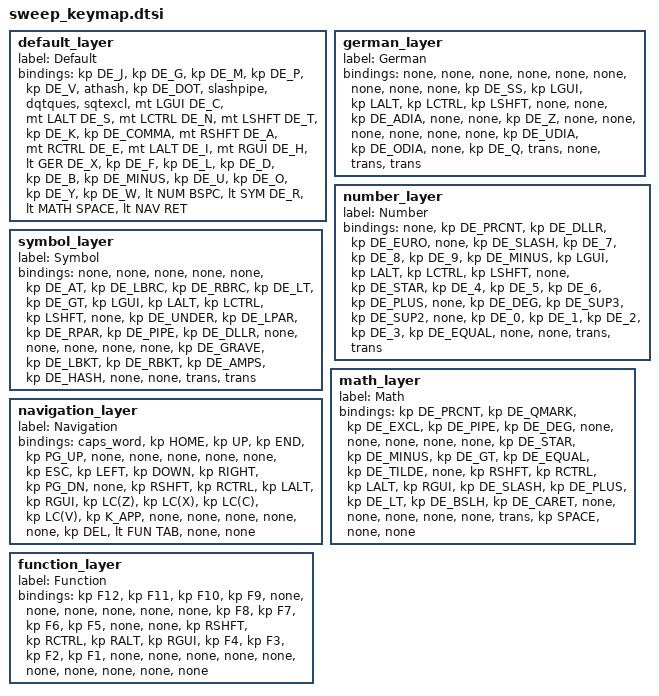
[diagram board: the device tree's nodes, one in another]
default_layer {
	label = "Default";
	bindings = <
	// --------------+---------------+---------------+---------------+--------------||---------------+---------------+---------------+---------------+---------------|
		&kp DE_J		&kp DE_G		&kp DE_M		&kp DE_P		&kp DE_V		&athash			&kp DE_DOT		&slashpipe		&dqtques		&sqtexcl 
	// --------------+---------------+---------------+---------------+--------------||---------------+---------------+---------------+---------------+---------------|
		&mt LGUI DE_C	&mt LALT DE_S	&mt LCTRL DE_N	&mt LSHFT DE_T	&kp DE_K		&kp DE_COMMA	&mt RSHFT DE_A	&mt RCTRL DE_E 	&mt LALT DE_I	&mt RGUI DE_H
	// --------------+---------------+---------------+---------------+--------------||---------------+---------------+---------------+---------------+---------------|
		&lt GER DE_X	&kp DE_F		&kp DE_L		&kp DE_D		&kp DE_B		&kp DE_MINUS   	&kp DE_U		&kp DE_O		&kp DE_Y		&kp DE_W	
	// --------------+---------------+---------------+---------------+--------------||---------------+---------------+---------------+---------------+---------------|
														&lt NUM BSPC	&lt SYM DE_R	&lt MATH SPACE	&lt NAV RET
							        				//---------------+--------------||---------------+---------------|
	>;
};

german_layer {
	label = "German";
	bindings = <
	// --------------+---------------+---------------+---------------+--------------||---------------+---------------+---------------+---------------+---------------|
		&none			&none			&none			&none			&none			&none			&none			&none			&none			&kp DE_SS 
	// --------------+---------------+---------------+---------------+--------------||---------------+---------------+---------------+---------------+---------------|
		&kp LGUI		&kp LALT		&kp LCTRL		&kp LSHFT		&none			&none			&kp DE_ADIA		&none			&none			&kp DE_Z
	// --------------+---------------+---------------+---------------+--------------||---------------+---------------+---------------+---------------+---------------|
		&none			&none			&none			&none			&none			&none	   		&kp DE_UDIA		&kp DE_ODIA		&none			&kp DE_Q	
	// --------------+---------------+---------------+---------------+--------------||---------------+---------------+---------------+---------------+---------------|
														&trans			&none			&trans			&trans
							            			//---------------+--------------||---------------+---------------|
	>;
};

number_layer {
	label = "Number";
	bindings = <
	// --------------+---------------+---------------+---------------+--------------||---------------+---------------+---------------+---------------+---------------|
		&none			&kp DE_PRCNT	&kp DE_DLLR		&kp DE_EURO		&none			&kp DE_SLASH	&kp DE_7		&kp DE_8		&kp DE_9		&kp DE_MINUS 
	// --------------+---------------+---------------+---------------+--------------||---------------+---------------+---------------+---------------+---------------|
		&kp LGUI		&kp LALT		&kp LCTRL		&kp LSHFT		&none			&kp DE_STAR		&kp DE_4		&kp DE_5		&kp DE_6		&kp DE_PLUS
	// --------------+---------------+---------------+---------------+--------------||---------------+---------------+---------------+---------------+---------------|
		&none			&kp DE_DEG		&kp DE_SUP3		&kp DE_SUP2		&none			&kp DE_0	   	&kp DE_1		&kp DE_2		&kp DE_3		&kp DE_EQUAL	
	// --------------+---------------+---------------+---------------+--------------||---------------+---------------+---------------+---------------+---------------|
														&none			&none			&trans			&trans
							            			//---------------+--------------||---------------+---------------|
	>;
};


symbol_layer {
	label = "Symbol";
	bindings = <
	// --------------+---------------+---------------+---------------+--------------||---------------+---------------+---------------+---------------+---------------|
		&none			&none			&none			&none			&none			&kp DE_AT		&kp DE_LBRC		&kp DE_RBRC		&kp DE_LT		&kp DE_GT
	// --------------+---------------+---------------+---------------+--------------||---------------+---------------+---------------+---------------+---------------|
		&kp LGUI		&kp LALT		&kp LCTRL		&kp LSHFT		&none			&kp DE_UNDER	&kp DE_LPAR	 	&kp DE_RPAR		&kp DE_PIPE		&kp DE_DLLR			
	// --------------+---------------+---------------+---------------+--------------||---------------+---------------+---------------+---------------+---------------|
		&none			&none			&none			&none			&none			&kp DE_GRAVE	&kp DE_LBKT 	&kp DE_RBKT		&kp DE_AMPS		&kp DE_HASH			
	// --------------+---------------+---------------+---------------+--------------||---------------+---------------+---------------+---------------+---------------|
														&none			&none 			&trans			&trans
							        				//---------------+--------------||---------------+---------------|
	>;
};

math_layer {
	label = "Math";
	bindings = <
	// --------------+---------------+---------------+---------------+--------------||---------------+---------------+---------------+---------------+---------------|
		&kp DE_PRCNT	&kp DE_QMARK	&kp DE_EXCL		&kp DE_PIPE		&kp DE_DEG		&none			&none			&none			&none			&none 
	// --------------+---------------+---------------+---------------+--------------||---------------+---------------+---------------+---------------+---------------|
		&kp DE_STAR		&kp DE_MINUS	&kp DE_GT		&kp DE_EQUAL	&kp DE_TILDE	&none			&kp RSHFT		&kp RCTRL 		&kp LALT		&kp RGUI	
	// --------------+---------------+---------------+---------------+--------------||---------------+---------------+---------------+---------------+---------------|
		&kp DE_SLASH	&kp DE_PLUS		&kp DE_LT		&kp DE_BSLH		&kp DE_CARET	&none   		&none			&none 			&none			&none	
	// --------------+---------------+---------------+---------------+--------------||---------------+---------------+---------------+---------------+---------------|
														&trans			&kp SPACE 		&none 			&none
							        				//---------------+--------------||---------------+---------------|
	>;
};

navigation_layer {
	label = "Navigation";
	bindings = <
	// --------------+---------------+---------------+---------------+--------------||---------------+---------------+---------------+---------------+---------------|
		&caps_word		&kp HOME		&kp UP			&kp END			&kp PG_UP		&none			&none			&none			&none			&none 
	// --------------+---------------+---------------+---------------+--------------||---------------+---------------+---------------+---------------+---------------|
		&kp ESC 		&kp LEFT		&kp DOWN		&kp RIGHT		&kp PG_DN		&none			&kp RSHFT		&kp RCTRL 		&kp LALT		&kp RGUI
	// --------------+---------------+---------------+---------------+--------------||---------------+---------------+---------------+---------------+---------------|
		&kp LC(Z)		&kp LC(X)		&kp LC(C)		&kp LC(V)		&kp K_APP		&none	    	&none			&none			&none			&none	
	// --------------+---------------+---------------+---------------+--------------||---------------+---------------+---------------+---------------+---------------|
														&kp DEL			&lt FUN TAB		&none			&none
							        				//---------------+--------------||---------------+---------------|
	>;
};

function_layer {
	label = "Function";
	bindings = <
	// --------------+---------------+---------------+---------------+--------------||---------------+---------------+---------------+---------------+---------------|
		&kp F12			&kp F11			&kp F10			&kp F9	 		&none	 		&none			&none			&none			&none			&none		
	// --------------+---------------+---------------+---------------+--------------||---------------+---------------+---------------+---------------+---------------|
		&kp F8			&kp F7 			&kp F6			&kp F5			&none 			&none 			&kp RSHFT		&kp RCTRL		&kp RALT		&kp RGUI		
	// --------------+---------------+---------------+---------------+--------------||---------------+---------------+---------------+---------------+---------------|
		&kp F4			&kp F3			&kp F2			&kp F1			&none 			&none			&none			&none			&none			&none		
	// --------------+---------------+---------------+---------------+--------------||---------------+---------------+---------------+---------------+---------------|
														&none			&none			&none			&none
							            			//---------------+--------------||---------------+---------------|
	>;
};
